AUTOSAR XML (schema 4-3-0)
package /Impl_SWC_DID_ARPkg
  swc implementation Impl_SWC_DID_type: programming-language=C, sw-version=1.0.0, vendor-id=0, behavior=SWC_DID_type_IB
    code-descriptors:
      code SRC: artifact-descriptors=autosar-engineering-object={short-label=EngObject, category=SWSRC}
    resource consumption ResourceConsumption
      memory section Mem_SWC_DID_CODE: size=0, sw-addrmethod=CODE, symbol=CODE
package /Interface_DID_ARPkg
  client server interface IF_DIDReadCDD
    operation CSOP_DIDGet_XWDMode
      4 x arg, all with server-argument-impl-policy=USE-ARGUMENT-TYPE:
        u8_XWDMode: type=uint8, direction=OUT
        u8_DIDSta_XWDMode: type=uint8, direction=OUT
        u16_DIDNum_XWDMode: type=uint16, direction=IN
        u16_DIDLen_XWDMode: type=uint16, direction=IN
    operation CSOP_DIDGet_DKCKey
      4 x arg, all with server-argument-impl-policy=USE-ARGUMENT-TYPE:
        u8Array8_DKCKey: type=u8Array8_DKCKey_type, direction=OUT
        u8_DIDSta_DKCKey: type=uint8, direction=OUT
        u16_DIDNum_DKCKey: type=uint16, direction=IN
        u16_DIDLen_DKCKey: type=uint16, direction=IN
    operation CSOP_DIDGet_DynoMode
      4 x arg, all with server-argument-impl-policy=USE-ARGUMENT-TYPE:
        u8_DynoMode: type=uint8, direction=OUT
        u8_DIDSta_DynoMode: type=uint8, direction=OUT
        u16_DIDNum_DynoMode: type=uint16, direction=IN
        u16_DIDLen_DynoMode: type=uint16, direction=IN
  client server interface IF_DIDWriteCDD
    16 x operation:
      CSOP_DIDSet_XWDMode
        arg u16_DIDNum_XWDMode: type=uint16, direction=IN, server-argument-impl-policy=USE-ARGUMENT-TYPE
        arg u16_DIDLen_XWDMode: type=uint16, direction=IN, server-argument-impl-policy=USE-ARGUMENT-TYPE
        arg u8_XWDMode: type=uint8, direction=IN, server-argument-impl-policy=USE-ARGUMENT-TYPE
      CSOP_DIDSet_DKCKey
        arg u16_DIDNum_DKCKey: type=uint16, direction=IN, server-argument-impl-policy=USE-ARGUMENT-TYPE
        arg u16_DIDLen_DKCKey: type=uint16, direction=IN, server-argument-impl-policy=USE-ARGUMENT-TYPE
        arg u8Array8_DKCKey: type=u8Array8_DKCKey_type, direction=IN, server-argument-impl-policy=USE-ARGUMENT-TYPE
      CSOP_DIDSet_DynoMode
        arg u16_DIDNum_DynoMode: type=uint16, direction=IN, server-argument-impl-policy=USE-ARGUMENT-TYPE
        arg u16_DIDLen_DynoMode: type=uint16, direction=IN, server-argument-impl-policy=USE-ARGUMENT-TYPE
        arg u8_DynoMode: type=uint8, direction=IN, server-argument-impl-policy=USE-ARGUMENT-TYPE
      CSOP_DIDSet_LFSensorID
        arg u16_DIDNum_LFSensorID: type=uint16, direction=IN, server-argument-impl-policy=USE-ARGUMENT-TYPE
        arg u16_DIDLen_LFSensorID: type=uint16, direction=IN, server-argument-impl-policy=USE-ARGUMENT-TYPE
        arg u8Array4_LFSensorID: type=u8Array4_LFSensorID_type, direction=IN, server-argument-impl-policy=USE-ARGUMENT-TYPE
      CSOP_DIDSet_RFSensorID
        arg u16_DIDNum_RFSensorID: type=uint16, direction=IN, server-argument-impl-policy=USE-ARGUMENT-TYPE
        arg u16_DIDLen_RFSensorID: type=uint16, direction=IN, server-argument-impl-policy=USE-ARGUMENT-TYPE
        arg u8Array4_RFSensorID: type=u8Array4_RFSensorID_type, direction=IN, server-argument-impl-policy=USE-ARGUMENT-TYPE
      CSOP_DIDSet_LRSensorID
        arg u16_DIDNum_LRSensorID: type=uint16, direction=IN, server-argument-impl-policy=USE-ARGUMENT-TYPE
        arg u16_DIDLen_LRSensorID: type=uint16, direction=IN, server-argument-impl-policy=USE-ARGUMENT-TYPE
        arg u8Array4_LRSensorID: type=u8Array4_LRSensorID_type, direction=IN, server-argument-impl-policy=USE-ARGUMENT-TYPE
      CSOP_DIDSet_RRSensorID
        arg u16_DIDNum_RRSensorID: type=uint16, direction=IN, server-argument-impl-policy=USE-ARGUMENT-TYPE
        arg u16_DIDLen_RRSensorID: type=uint16, direction=IN, server-argument-impl-policy=USE-ARGUMENT-TYPE
        arg u8Array4_RRSensorID: type=u8Array4_RRSensorID_type, direction=IN, server-argument-impl-policy=USE-ARGUMENT-TYPE
      CSOP_DIDSet_WhlPres
        arg u16_DIDNum_WhlPres: type=uint16, direction=IN, server-argument-impl-policy=USE-ARGUMENT-TYPE
        arg u16_DIDLen_WhlPres: type=uint16, direction=IN, server-argument-impl-policy=USE-ARGUMENT-TYPE
        arg u8Array4_WhlPres: type=u8Array4_WhlPres_type, direction=IN, server-argument-impl-policy=USE-ARGUMENT-TYPE
      CSOP_DIDSet_WhlTmp
        arg u16_DIDNum_WhlTmp: type=uint16, direction=IN, server-argument-impl-policy=USE-ARGUMENT-TYPE
        arg u16_DIDLen_WhlTmp: type=uint16, direction=IN, server-argument-impl-policy=USE-ARGUMENT-TYPE
        arg u8Array4_WhlTmp: type=u8Array4_WhlTmp_type, direction=IN, server-argument-impl-policy=USE-ARGUMENT-TYPE
      CSOP_DIDSet_WhlSensorBattSta
        arg u16_DIDNum_WhlSensorBattSta: type=uint16, direction=IN, server-argument-impl-policy=USE-ARGUMENT-TYPE
        arg u16_DIDLen_WhlSensorBattSta: type=uint16, direction=IN, server-argument-impl-policy=USE-ARGUMENT-TYPE
        arg u8_WhlSensorBattSta: type=uint8, direction=IN, server-argument-impl-policy=USE-ARGUMENT-TYPE
      CSOP_DIDSet_LFLowPresThre
        arg u16_DIDNum_LFLowPresThre: type=uint16, direction=IN, server-argument-impl-policy=USE-ARGUMENT-TYPE
        arg u16_DIDLen_LFLowPresThre: type=uint16, direction=IN, server-argument-impl-policy=USE-ARGUMENT-TYPE
        arg u8_LFLowPresThre: type=uint8, direction=IN, server-argument-impl-policy=USE-ARGUMENT-TYPE
      CSOP_DIDSet_RFLowPresThre
        arg u16_DIDNum_RFLowPresThre: type=uint16, direction=IN, server-argument-impl-policy=USE-ARGUMENT-TYPE
        arg u16_DIDLen_RFLowPresThre: type=uint16, direction=IN, server-argument-impl-policy=USE-ARGUMENT-TYPE
        arg u8_RFLowPresThre: type=uint8, direction=IN, server-argument-impl-policy=USE-ARGUMENT-TYPE
      CSOP_DIDSet_LRLowPresThre
        arg u16_DIDNum_LRLowPresThre: type=uint16, direction=IN, server-argument-impl-policy=USE-ARGUMENT-TYPE
        arg u16_DIDLen_LRLowPresThre: type=uint16, direction=IN, server-argument-impl-policy=USE-ARGUMENT-TYPE
        arg u8_LRLowPresThre: type=uint8, direction=IN, server-argument-impl-policy=USE-ARGUMENT-TYPE
      CSOP_DIDSet_RRLowPresThre
        arg u16_DIDNum_RRLowPresThre: type=uint16, direction=IN, server-argument-impl-policy=USE-ARGUMENT-TYPE
        arg u16_DIDLen_RRLowPresThre: type=uint16, direction=IN, server-argument-impl-policy=USE-ARGUMENT-TYPE
        arg u8_RRLowPresThre: type=uint8, direction=IN, server-argument-impl-policy=USE-ARGUMENT-TYPE
      CSOP_DIDSet_SensorMode
        arg u16_DIDNum_SensorMode: type=uint16, direction=IN, server-argument-impl-policy=USE-ARGUMENT-TYPE
        arg u16_DIDLen_SensorMode: type=uint16, direction=IN, server-argument-impl-policy=USE-ARGUMENT-TYPE
        arg u8_SensorMode: type=uint8, direction=IN, server-argument-impl-policy=USE-ARGUMENT-TYPE
      CSOP_DIDSet_TPMSLearnSta
        arg u16_DIDNum_TPMSLearnSta: type=uint16, direction=IN, server-argument-impl-policy=USE-ARGUMENT-TYPE
        arg u16_DIDLen_TPMSLearnSta: type=uint16, direction=IN, server-argument-impl-policy=USE-ARGUMENT-TYPE
        arg u8_TPMSLearnSta: type=uint8, direction=IN, server-argument-impl-policy=USE-ARGUMENT-TYPE
package /SWC_DID_ARPkg
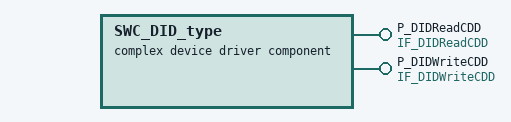
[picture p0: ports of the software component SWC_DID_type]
  complex device driver sw component type SWC_DID_type
    provide port P_DIDReadCDD: provided-interface=IF_DIDReadCDD
    provide port P_DIDWriteCDD: provided-interface=IF_DIDWriteCDD
    behavior SWC_DID_type_IB: handle-termination-and-restart=NO-SUPPORT
      19 x operation invoked event:
        oie_P_DIDReadCDD_CSOP_DIDGet_XWDMode: start-on-event=run_DIDGet_XWDMode, operation=P_DIDReadCDD.CSOP_DIDGet_XWDMode
        oie_P_DIDWriteCDD_CSOP_DIDSet_XWDMode: start-on-event=run_DIDSet_XWDMode, operation=P_DIDWriteCDD.CSOP_DIDSet_XWDMode
        oie_P_DIDReadCDD_CSOP_DIDGet_DKCKey: start-on-event=run_DIDGet_DKCKey, operation=P_DIDReadCDD.CSOP_DIDGet_DKCKey
        oie_P_DIDWriteCDD_CSOP_DIDSet_DKCKey: start-on-event=run_DIDSet_DKCKey, operation=P_DIDWriteCDD.CSOP_DIDSet_DKCKey
        oie_P_DIDReadCDD_CSOP_DIDGet_DynoMode: start-on-event=run_DIDGet_DynoMode, operation=P_DIDReadCDD.CSOP_DIDGet_DynoMode
        oie_P_DIDWriteCDD_CSOP_DIDSet_DynoMode: start-on-event=run_DIDSet_DynoMode, operation=P_DIDWriteCDD.CSOP_DIDSet_DynoMode
        oie_P_DIDWriteCDD_CSOP_DIDSet_LFSensorID: start-on-event=run_DIDSet_LFSensorID, operation=P_DIDWriteCDD.CSOP_DIDSet_LFSensorID
        oie_P_DIDWriteCDD_CSOP_DIDSet_RFSensorID: start-on-event=run_DIDSet_RFSensorID, operation=P_DIDWriteCDD.CSOP_DIDSet_RFSensorID
        oie_P_DIDWriteCDD_CSOP_DIDSet_LRSensorID: start-on-event=run_DIDSet_LRSensorID, operation=P_DIDWriteCDD.CSOP_DIDSet_LRSensorID
        oie_P_DIDWriteCDD_CSOP_DIDSet_RRSensorID: start-on-event=run_DIDSet_RRSensorID, operation=P_DIDWriteCDD.CSOP_DIDSet_RRSensorID
        oie_P_DIDWriteCDD_CSOP_DIDSet_WhlPres: start-on-event=run_DIDSet_WhlPres, operation=P_DIDWriteCDD.CSOP_DIDSet_WhlPres
        oie_P_DIDWriteCDD_CSOP_DIDSet_WhlTmp: start-on-event=run_DIDSet_WhlTmp, operation=P_DIDWriteCDD.CSOP_DIDSet_WhlTmp
        oie_P_DIDWriteCDD_CSOP_DIDSet_WhlSensorBattSta: start-on-event=run_DIDSet_WhlSensorBattSta, operation=P_DIDWriteCDD.CSOP_DIDSet_WhlSensorBattSta
        oie_P_DIDWriteCDD_CSOP_DIDSet_LFLowPresThre: start-on-event=run_DIDSet_LFLowPresThre, operation=P_DIDWriteCDD.CSOP_DIDSet_LFLowPresThre
        oie_P_DIDWriteCDD_CSOP_DIDSet_RFLowPresThre: start-on-event=run_DIDSet_RFLowPresThre, operation=P_DIDWriteCDD.CSOP_DIDSet_RFLowPresThre
        oie_P_DIDWriteCDD_CSOP_DIDSet_LRLowPresThre: start-on-event=run_DIDSet_LRLowPresThre, operation=P_DIDWriteCDD.CSOP_DIDSet_LRLowPresThre
        oie_P_DIDWriteCDD_CSOP_DIDSet_RRLowPresThre: start-on-event=run_DIDSet_RRLowPresThre, operation=P_DIDWriteCDD.CSOP_DIDSet_RRLowPresThre
        oie_P_DIDWriteCDD_CSOP_DIDSet_SensorMode: start-on-event=run_DIDSet_SensorMode, operation=P_DIDWriteCDD.CSOP_DIDSet_SensorMode
        oie_P_DIDWriteCDD_CSOP_DIDSet_TPMSLearnSta: start-on-event=run_DIDSet_TPMSLearnSta, operation=P_DIDWriteCDD.CSOP_DIDSet_TPMSLearnSta
      port-api-options:
        enable-take-address=false, indirect-api=false, port=P_DIDWriteCDD
        enable-take-address=false, indirect-api=false, port=P_DIDReadCDD
      19 x runnable:
        run_DIDGet_XWDMode
        run_DIDSet_XWDMode
        run_DIDGet_DKCKey
        run_DIDSet_DKCKey
        run_DIDGet_DynoMode
        run_DIDSet_DynoMode
        run_DIDSet_LFSensorID
        run_DIDSet_RFSensorID
        run_DIDSet_LRSensorID
        run_DIDSet_RRSensorID
        run_DIDSet_WhlPres
        run_DIDSet_WhlTmp
        run_DIDSet_WhlSensorBattSta
        run_DIDSet_LFLowPresThre
        run_DIDSet_RFLowPresThre
        run_DIDSet_LRLowPresThre
        run_DIDSet_RRLowPresThre
        run_DIDSet_SensorMode
        run_DIDSet_TPMSLearnSta
package /TypeDef_DID_ARPkg
  7 x impl type, all with category=ARRAY:
    u8Array8_DKCKey_type
      element u8_Element: category=VALUE, array-size=8, array-size-semantics=FIXED-SIZE, base-type=uint8
    u8Array4_LFSensorID_type
      element u8_Element: category=VALUE, array-size=4, array-size-semantics=FIXED-SIZE, base-type=uint8
    u8Array4_RFSensorID_type
      element u8_Element: category=VALUE, array-size=4, array-size-semantics=FIXED-SIZE, base-type=uint8
    u8Array4_LRSensorID_type
      element u8_Element: category=VALUE, array-size=4, array-size-semantics=FIXED-SIZE, base-type=uint8
    u8Array4_RRSensorID_type
      element u8_Element: category=VALUE, array-size=4, array-size-semantics=FIXED-SIZE, base-type=uint8
    u8Array4_WhlPres_type
      element u8_Element: category=VALUE, array-size=4, array-size-semantics=FIXED-SIZE, base-type=uint8
    u8Array4_WhlTmp_type
      element u8_Element: category=VALUE, array-size=4, array-size-semantics=FIXED-SIZE, base-type=uint8
